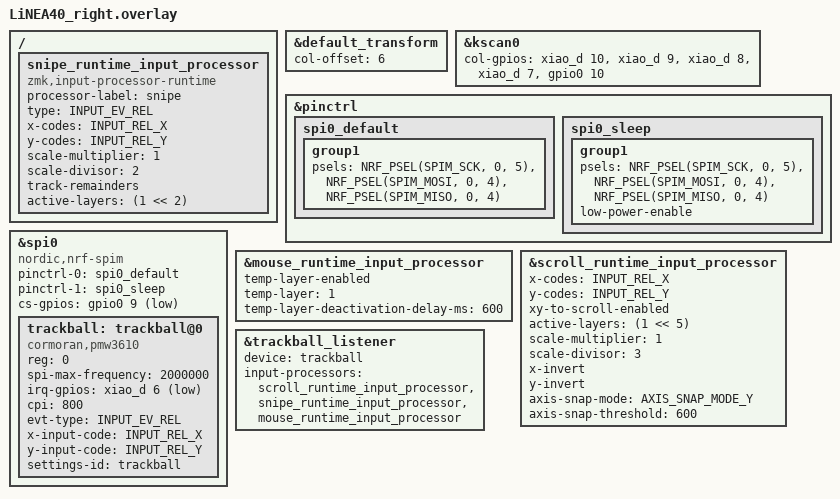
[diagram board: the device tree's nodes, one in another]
#include <zephyr/dt-bindings/input/input-event-codes.h>
#include <input/processors.dtsi>
#include <input/processors/runtime-input-processor.dtsi>
#include <dt-bindings/zmk/runtime_input_processor.h>

#include "LiNEA40.dtsi"

&default_transform {
    col-offset = <6>;
};

&kscan0 {
    col-gpios
        = <&xiao_d 10 GPIO_ACTIVE_HIGH> //col0-D10
        , <&xiao_d 9 GPIO_ACTIVE_HIGH>  //col1-D9
        , <&xiao_d 8 GPIO_ACTIVE_HIGH>  //col2-D8
        , <&xiao_d 7 GPIO_ACTIVE_HIGH>  //col3-D7
        , <&gpio0 10 GPIO_ACTIVE_HIGH>  //col4-NFC2
        ;
};

&pinctrl {
    spi0_default: spi0_default {
        group1 {
            psels = <NRF_PSEL(SPIM_SCK, 0, 5)>   // SCLK-D5
                  , <NRF_PSEL(SPIM_MOSI, 0, 4)>  // SDIO-D4
                  , <NRF_PSEL(SPIM_MISO, 0, 4)>  // SDIO-D4
                  ;
        };
    };

    spi0_sleep: spi0_sleep {
        group1 {
            psels = <NRF_PSEL(SPIM_SCK, 0, 5)>   // SCLK-D5
                  , <NRF_PSEL(SPIM_MOSI, 0, 4)>  // SDIO-D4
                  , <NRF_PSEL(SPIM_MISO, 0, 4)>  // SDIO-D4
                  ;
            low-power-enable;
        };
    };
};

&spi0 {
    status = "okay";
    compatible = "nordic,nrf-spim";
    pinctrl-0 = <&spi0_default>;
    pinctrl-1 = <&spi0_sleep>;
    pinctrl-names = "default", "sleep";
    cs-gpios = <&gpio0 9 GPIO_ACTIVE_LOW>; //NCS-NFC1

    trackball: trackball@0 {
        status = "okay";
        compatible = "cormoran,pmw3610";
        reg = <0>;
        spi-max-frequency = <2000000>;
        irq-gpios = <&xiao_d 6 (GPIO_ACTIVE_LOW | GPIO_PULL_UP)>; //MOT-D6
        cpi = <800>;
        evt-type = <INPUT_EV_REL>;
        x-input-code = <INPUT_REL_X>;
        y-input-code = <INPUT_REL_Y>;
        settings-id = "trackball";
    };
};

// オートマウス・スナイプ・スクロールは DYA Studio の Trackball タブから変更できる。ここは初期値。
/ {
    // レイヤー2 (MARK) の間はカーソル速度を半分にする
    snipe_runtime_input_processor: snipe_runtime_input_processor {
        compatible = "zmk,input-processor-runtime";
        processor-label = "snipe";
        type = <INPUT_EV_REL>;
        x-codes = <INPUT_REL_X>;
        y-codes = <INPUT_REL_Y>;
        scale-multiplier = <1>;
        scale-divisor = <2>;
        track-remainders;
        active-layers = <(1 << 2)>;

        #input-processor-cells = <0>;
    };
};

// カーソル移動でレイヤー1 (MOUSE) を自動で有効にする
&mouse_runtime_input_processor {
    temp-layer-enabled;
    temp-layer = <1>;
    temp-layer-deactivation-delay-ms = <600>;
};

// レイヤー5 (SCROLL) の間はカーソル移動をスクロールに変換する
&scroll_runtime_input_processor {
    x-codes = <INPUT_REL_X>;
    y-codes = <INPUT_REL_Y>;
    xy-to-scroll-enabled;
    active-layers = <(1 << 5)>;
    scale-multiplier = <1>;
    scale-divisor = <3>;
    x-invert;
    y-invert;

    axis-snap-mode = <AXIS_SNAP_MODE_Y>;
    axis-snap-threshold = <600>;
};

&trackball_listener {
    status = "okay";
    device = <&trackball>;
    // スクロール変換を先に通し、スクロール中はオートマウスが働かないようにする
    input-processors = <&scroll_runtime_input_processor &snipe_runtime_input_processor &mouse_runtime_input_processor>;
};
